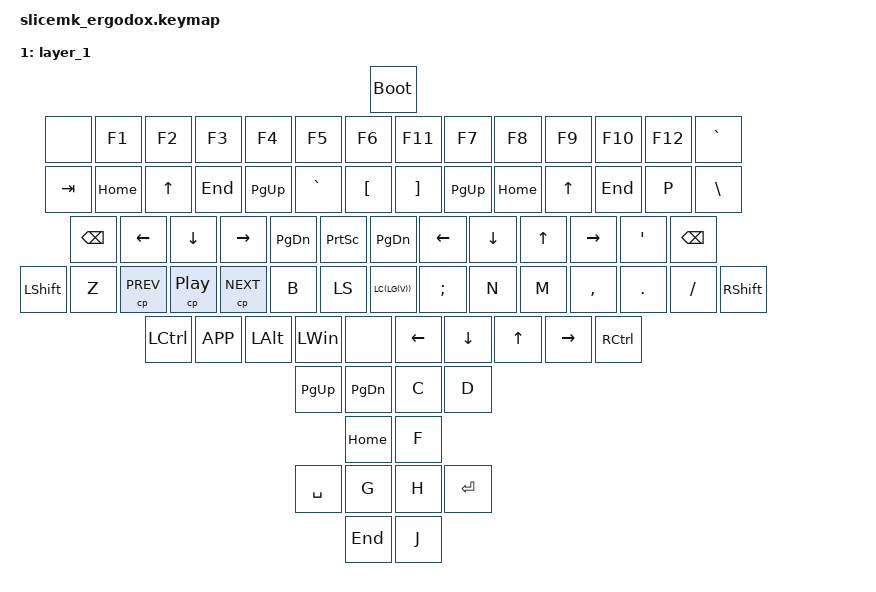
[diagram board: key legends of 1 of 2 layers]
#include <behaviors.dtsi>
#include <dt-bindings/zmk/bt.h>
#include <dt-bindings/zmk/keys.h>
#include <dt-bindings/zmk/outputs.h>

#define DEFAULT 0
#define AZFUNC   1

/ {
        keymap {
                compatible = "zmk,keymap";



                layer_0 {
                        bindings = <
    &bootloader
    &kp ESC   &kp N1  &kp N2  &kp N3  &kp N4  &kp N5  &kp N6   &kp MINUS      &kp N7  &kp N8  &kp N9  &kp N0  &kp EQUAL  &kp GRAVE
    &kp TAB    &kp Q      &kp W      &kp E      &kp R      &kp T      &kp LBKT   &kp RBKT &kp Y      &kp U      &kp I      &kp O      &kp P      &kp BSLH
    &kp DEL    &kp A      &kp S      &kp D      &kp F      &kp G                            &kp H      &kp J      &kp K      &kp L      &kp SQT   &kp BSPC
    &kp LSHFT      &kp Z      &kp X      &kp C      &kp V      &kp B      &kp LS(LC(LG(V))) &kp SEMI &kp N      &kp M      &kp CMMA   &kp DOT    &kp FSLH   &kp RSHFT
    &kp LCTRL      &kp K_APP      &kp LALT   &kp LWIN   &mo AZFUNC                                               &kp A   &kp S   &kp UP   &kp D      &kp F
                                                           &kp LEFT    &kp RIGHT   &kp PG_UP    &kp PG_DN
                                                                      &kp UP   &kp HOME
                                                &kp SPC    &kp RET                         &mo AZFUNC   &kp RET
                                                                      &kp DOWN   &kp END						

                        >;
                };

                layer_1 {
                        bindings = <
    &bootloader
    &none      &kp F1     &kp F2     &kp F3     &kp F4      &kp F5     &kp F6     &kp F11     &kp F7      &kp F8     &kp F9    &kp F10    &kp F12      &kp GRAVE
    &kp TAB    &kp HOME      &kp UP      &kp END      &kp PG_UP      &kp GRAVE      &kp LBKT   &kp RBKT &kp PG_UP      &kp HOME      &kp UP      &kp END      &kp P      &kp BSLH
    &kp BSPC    &kp LEFT      &kp DOWN      &kp RIGHT      &kp PG_DN      &kp PSCRN                            &kp PG_DN      &kp LEFT   &kp DOWN      &kp UP      &kp RIGHT      &kp SQT   &kp BSPC
    &kp LSHFT      &kp Z      &cp C_PREV      &cp C_PP      &cp C_NEXT      &kp B      &kp LS(LC(LG(V))) &kp SEMI &kp N      &kp M      &kp CMMA   &kp DOT    &kp FSLH   &kp RSHFT
    &kp LCTRL      &kp K_APP      &kp LALT   &kp LWIN   &none                                               &kp LEFT   &kp DOWN   &kp UP   &kp RIGHT      &kp RCTL
                                                           &kp PG_UP    &kp PG_DN   &kp C    &kp D
                                                                      &kp HOME   &kp F
                                                &kp SPC    &kp G                         &kp H   &kp RET
                                                                      &kp END   &kp J
                        >;
                };

        };
};
